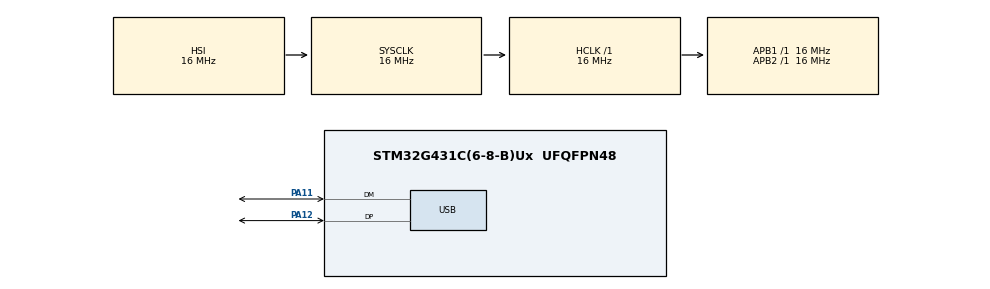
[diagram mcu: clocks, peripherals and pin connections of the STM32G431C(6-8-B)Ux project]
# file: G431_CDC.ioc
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Mcu.Family=STM32G4
Mcu.Name=STM32G431C(6-8-B)Ux
Mcu.Package=UFQFPN48
NVIC.PriorityGroup=NVIC_PRIORITYGROUP_4
NVIC.USB_LP_IRQn=true\:0\:0\:false\:false\:true\:false\:true\:true
PA11.Mode=Device
PA11.Signal=USB_DM
PA12.Mode=Device
PA12.Signal=USB_DP
PA13.Mode=Serial_Wire
PA13.Signal=SYS_JTMS-SWDIO
PA14.Mode=Serial_Wire
PA14.Signal=SYS_JTCK-SWCLK
PF0-OSC_IN.Mode=HSE-External-Oscillator
PF0-OSC_IN.Signal=RCC_OSC_IN
PF1-OSC_OUT.Mode=HSE-External-Oscillator
PF1-OSC_OUT.Signal=RCC_OSC_OUT
ProjectManager.HeapSize=0x200
ProjectManager.StackSize=0x400
ProjectManager.TargetToolchain=STM32CubeIDE
RCC.AHBFreq_Value=16000000
RCC.APB1Freq_Value=16000000
RCC.APB1TimFreq_Value=16000000
RCC.APB2Freq_Value=16000000
RCC.APB2TimFreq_Value=16000000
RCC.CortexFreq_Value=16000000
RCC.EXTERNAL_CLOCK_VALUE=12288000
RCC.HCLKFreq_Value=16000000
RCC.HSE_VALUE=8000000
RCC.HSI48_VALUE=48000000
RCC.HSI_VALUE=16000000
RCC.LSE_VALUE=32768
RCC.PLLN=12
RCC.PLLSourceVirtual=RCC_PLLSOURCE_HSE
RCC.SYSCLKFreq_VALUE=16000000
RCC.USBFreq_Value=48000000
RCC.VCOOutputFreq_Value=96000000
USB_DEVICE.CLASS_NAME_FS=CDC
USB_DEVICE.VirtualMode=Cdc
USB_DEVICE.VirtualModeFS=Cdc_FS
VP_SYS_VS_DBSignals.Mode=DisableDeadBatterySignals
VP_USB_DEVICE_VS_USB_DEVICE_CDC_FS.Mode=CDC_FS
board=custom

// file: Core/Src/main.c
/* USER CODE BEGIN Header */
/**
  ******************************************************************************
  * @file           : main.c
  * @brief          : Main program body
  ******************************************************************************
  * @attention
  *
  * Copyright (c) 2025 STMicroelectronics.
  * All rights reserved.
  *
  * This software is licensed under terms that can be found in the LICENSE file
  * in the root directory of this software component.
  * If no LICENSE file comes with this software, it is provided AS-IS.
  *
  ******************************************************************************
  */
/* USER CODE END Header */
#include "main.h"
#include "usb_device.h"
#include "usbd_cdc_if.h"
#include <string.h>
#include <stdint.h>
#include "cdc_rx.h"
#include "hil_tx.h"
#include "foc_maths.h"

/* USER CODE BEGIN PTD */
/* simple RX buffer */

/* for rate-limited printing */
uint32_t last_print_ms = 0;
Currents_t rx_currents;
volatile uint8_t frame_ready;
/* USER CODE END PTD */
float id;
float iq;

void SystemClock_Config(void);
static void MX_GPIO_Init(void);

int main(void)
{

  /* MCU Configuration--------------------------------------------------------*/

  /* Reset of all peripherals, Initializes the Flash interface and the Systick. */
  HAL_Init();

  /* Configure the system clock */
  SystemClock_Config();

  /* Initialize all configured peripherals */
  MX_GPIO_Init();
  MX_USB_Device_Init();

  //int i =0;
  /*while(i <= 4){
  	  CDC_Print("USB CDC ACTIVE\r\n");
  	  HAL_Delay(1000);
  }*/

  /* Infinite loop */
  /* USER CODE BEGIN WHILE */
  HAL_Delay(1000);  // wait for USB enumeration

/* USB C BINARY FRAME PARSE CHECK :
  uint8_t test_frame[14] = {
      0xAA,
      0x00, 0x00, 0x80, 0x3F, //1.0f
      0x00, 0x00, 0x00, 0x40, //2.0f
      0x00, 0x00, 0x40, 0x40, //3.0fS
	  0x55

  };

  while (1)
  {
      static uint32_t last_tx = 0;

      if (HAL_GetTick() - last_tx > 500)
      {
          last_tx = HAL_GetTick();

          while (CDC_Transmit_FS(test_frame, 14) == USBD_BUSY);
      }
  }

  // USER CODE END 3

  //echo_frame transmit

/*while(1){
  static uint32_t last_tx = 0;
  if (frame_ready && (HAL_GetTick() - last_tx) > 500)
  {
      frame_ready = 0;
      last_tx = HAL_GetTick();

      uint8_t echo_frame[14];

      echo_frame[0]  = 0xAA;   // SOF
      echo_frame[13] = 0x55;   // EOF

      memcpy(&echo_frame[1],  &rx_currents.ia, 4);  // ia @ [1..4]
      memcpy(&echo_frame[5],  &rx_currents.ib, 4);  // ib @ [5..8]
      memcpy(&echo_frame[9],  &rx_currents.ic, 4);  // ic @ [9..12]

      while (CDC_Transmit_FS(echo_frame, 14) == USBD_BUSY);
  }
}
  }*/
  while (1)
      {
          /* 1️⃣ If new RX frame arrived */
          if (frame_ready)
          {
              frame_ready = 0;

              /* 2️⃣ Run math */
              IAlphaBeta_t iab;
              clarke_transform(
                  rx_currents.ia,
                  rx_currents.ib,
                  rx_currents.ic,
                  &iab
              );

              Park(
                  iab.i_alpha,
                  iab.i_beta,
                  rx_currents.theta,
                  &id,
                  &iq
              );
          }

          /* 3️⃣ Periodic TX (rate-limited) */
          static uint32_t last_tx = 0;
          if (HAL_GetTick() - last_tx >= 10)
          {
              last_tx = HAL_GetTick();

              float tx_vars[6] = {
                  rx_currents.ia,
                  rx_currents.ib,
                  rx_currents.ic,
                  id,
                  iq,
				  rx_currents.theta
              };

              HIL_SendFloats(tx_vars, 6);
          }
      }

      // other non-blocking work here

}

void SystemClock_Config(void)
{
  RCC_OscInitTypeDef RCC_OscInitStruct = {0};
  RCC_ClkInitTypeDef RCC_ClkInitStruct = {0};

  /** Configure the main internal regulator output voltage
  */
  HAL_PWREx_ControlVoltageScaling(PWR_REGULATOR_VOLTAGE_SCALE1);

  /** Initializes the RCC Oscillators according to the specified parameters
  * in the RCC_OscInitTypeDef structure.
  */
  RCC_OscInitStruct.OscillatorType = RCC_OSCILLATORTYPE_HSI|RCC_OSCILLATORTYPE_HSE;
  RCC_OscInitStruct.HSEState = RCC_HSE_ON;
  RCC_OscInitStruct.HSIState = RCC_HSI_ON;
  RCC_OscInitStruct.HSICalibrationValue = RCC_HSICALIBRATION_DEFAULT;
  RCC_OscInitStruct.PLL.PLLState = RCC_PLL_ON;
  RCC_OscInitStruct.PLL.PLLSource = RCC_PLLSOURCE_HSE;
  RCC_OscInitStruct.PLL.PLLM = RCC_PLLM_DIV1;
  RCC_OscInitStruct.PLL.PLLN = 12;
  RCC_OscInitStruct.PLL.PLLP = RCC_PLLP_DIV2;
  RCC_OscInitStruct.PLL.PLLQ = RCC_PLLQ_DIV2;
  RCC_OscInitStruct.PLL.PLLR = RCC_PLLR_DIV2;
  if (HAL_RCC_OscConfig(&RCC_OscInitStruct) != HAL_OK)
  {
    Error_Handler();
  }

  /** Initializes the CPU, AHB and APB buses clocks
  */
  RCC_ClkInitStruct.ClockType = RCC_CLOCKTYPE_HCLK|RCC_CLOCKTYPE_SYSCLK
                              |RCC_CLOCKTYPE_PCLK1|RCC_CLOCKTYPE_PCLK2;
  RCC_ClkInitStruct.SYSCLKSource = RCC_SYSCLKSOURCE_HSI;
  RCC_ClkInitStruct.AHBCLKDivider = RCC_SYSCLK_DIV1;
  RCC_ClkInitStruct.APB1CLKDivider = RCC_HCLK_DIV1;
  RCC_ClkInitStruct.APB2CLKDivider = RCC_HCLK_DIV1;

  if (HAL_RCC_ClockConfig(&RCC_ClkInitStruct, FLASH_LATENCY_0) != HAL_OK)
  {
    Error_Handler();
  }
}

static void MX_GPIO_Init(void) {

    /* GPIO Ports Clock Enable */
    __HAL_RCC_GPIOF_CLK_ENABLE();
    __HAL_RCC_GPIOA_CLK_ENABLE();

  }

void Error_Handler(void)
{
  __disable_irq();
  while (1)
  {
  }
}
